# nrf9230_engb_cellcore register map
Vendor: Nordic Semiconductor; Series: nRF92; File version: 1
CPU: CM33 r0p4, little endian, MPU, FPU, 3 interrupt priority bits, 480 interrupts, 8 SAU regions
Registers are 32-bit, read-write, reset 0x0 unless marked. A register's access mark holds for its fields unless they carry their own. Offsets are from the block's base; [hi:lo] are bit positions; lines under a group give offsets from that group; {n}, {i} and the like mark numbered series; 'fields as' and 'values as' point back to an identical list.

## DPPIC0_NS — Distributed programmable peripheral interconnect controller 0
Base 0x44021000
Same registers: DPPIC1_NS 0x44032000, GLOBAL_DPPIC120_NS 0x4F8E1000, GLOBAL_DPPIC130_NS 0x4F922000, GLOBAL_DPPIC131_NS 0x4F981000, GLOBAL_DPPIC132_NS 0x4F991000, GLOBAL_DPPIC133_NS 0x4F9A1000, GLOBAL_DPPIC134_NS 0x4F9B1000, GLOBAL_DPPIC135_NS 0x4F9C1000, GLOBAL_DPPIC136_NS 0x4F9D1000, DPPIC0_S 0x54021000, DPPIC1_S 0x54032000, GLOBAL_DPPIC120_S 0x5F8E1000, GLOBAL_DPPIC130_S 0x5F922000, GLOBAL_DPPIC131_S 0x5F981000, GLOBAL_DPPIC132_S 0x5F991000, GLOBAL_DPPIC133_S 0x5F9A1000, GLOBAL_DPPIC134_S 0x5F9B1000, GLOBAL_DPPIC135_S 0x5F9C1000, GLOBAL_DPPIC136_S 0x5F9D1000
{0x0+8i} TASKS_CHG[{i}] (i=0..3) group — Channel group tasks
  0x00 EN wo — Description cluster: Enable channel group n
    [0] EN — Enable channel group n
      1=Trigger task
  0x04 DIS wo — Description cluster: Disable channel group n
    [0] DIS — Disable channel group n
      1=Trigger task
{0x80+8i} SUBSCRIBE_CHG[{i}] (i=0..3) group — Subscribe configuration for tasks
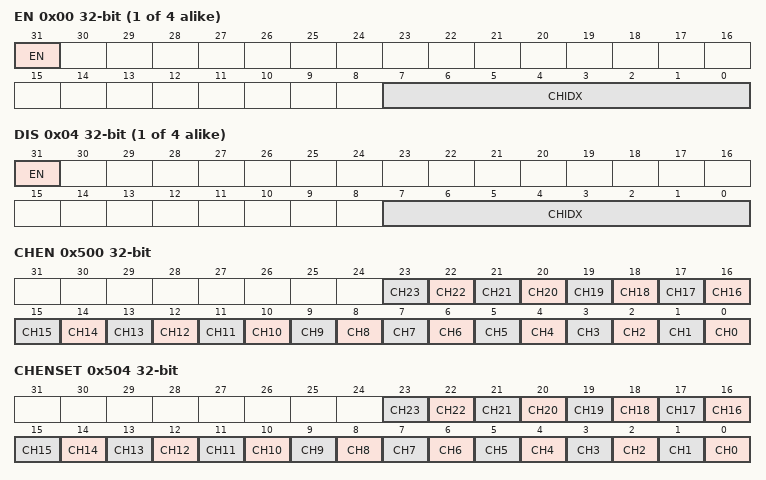
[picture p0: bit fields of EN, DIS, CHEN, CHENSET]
  0x00 EN — Description cluster: Subscribe configuration for task CHG[n].EN
    [31] EN
      0=Disabled (Disable subscription); 1=Enabled (Enable subscription)
    [7:0] CHIDX — DPPI channel that task CHG[n].EN will subscribe to
  0x04 DIS — Description cluster: Subscribe configuration for task CHG[n].DIS
    [31] EN
      values as SUBSCRIBE_CHG[0].EN.EN
    [7:0] CHIDX — DPPI channel that task CHG[n].DIS will subscribe to
0x500 CHEN — Channel enable register
  [all] fields
    0=Disabled (Disable channel); 1=Enabled (Enable channel)
  [n] CH{n} (n=0..23) — Enable or disable channel {n}
0x504 CHENSET write-1-sets — Channel enable set register
  [all] fields
    on read: 0=Disabled (Read: Channel disabled); 1=Enabled (Read: Channel enabled) | on write: 1=Set (Write: Enable channel)
  [n] CH{n} (n=0..23) — Channel {n} enable set register. Writing 0 has no effect.
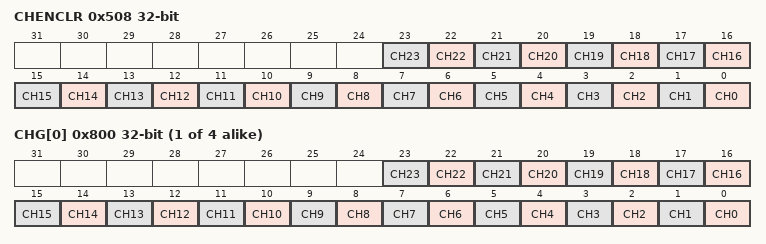
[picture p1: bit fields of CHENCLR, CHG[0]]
0x508 CHENCLR write-1-clears — Channel enable clear register
  [all] fields
    on read: 0=Disabled (Read: Channel disabled); 1=Enabled (Read: Channel enabled) | on write: 1=Clear (Write: Disable channel)
  [n] CH{n} (n=0..23) — Channel {n} enable clear register. Writing 0 has no effect.
{0x800+4i} CHG[{i}] (i=0..3) — Description collection: Channel group n Note: Writes to this register are ignored if either SUBSCRIBE_CHG[n].EN or SUBSCRIBE_CHG[n].DIS is enabled
  [all] fields
    0=Excluded; 1=Included
  [n] CH{n} (n=0..23) — Include or exclude channel {n}

## LFCLKCALIBMEAS_NS — LFCLK calibration measurement 0
Base 0x44023000
Same registers: LFCLKCALIBMEAS_S 0x54023000
0x00 TASKS_START wo — Start Measuring
  [0] TASKS_START
    1=Trigger task
0x04 TASKS_STOP wo — Switch LfClkCalibMeas to STOPPED state. Brings LfClkCalibMeas from SHUTDOWN state to a configurable state before a measurement is launched.
  [0] TASKS_STOP
    1=Trigger task
0x08 TASKS_SHUTDOWN wo — Shut down LfClkCalibMeas
  [0] TASKS_SHUTDOWN
    1=Trigger task
0x100 EVENTS_COMPLETE — Measurement completed
  [0] EVENTS_COMPLETE
    0=NotGenerated (Event not generated); 1=Generated (Event generated)
0x300 INTEN — Enable or disable interrupt
  [0] COMPLETE — Enable or disable interrupt for event COMPLETE
    0=Disabled; 1=Enabled
0x304 INTENSET — Enable interrupt
  [0] COMPLETE — Write '1' to enable interrupt for event COMPLETE
    on read: 0=Disabled (Read: Disabled); 1=Enabled (Read: Enabled) | on write: 1=Set (Enable)
0x308 INTENCLR — Disable interrupt
  [0] COMPLETE — Write '1' to disable interrupt for event COMPLETE
    on read: 0=Disabled (Read: Disabled); 1=Enabled (Read: Enabled) | on write: 1=Clear (Disable)
0x30C INTPEND ro — Pending interrupts
  [0] COMPLETE — Read pending status of interrupt for event COMPLETE
    on read: 0=NotPending (Read: Not pending); 1=Pending (Read: Pending)
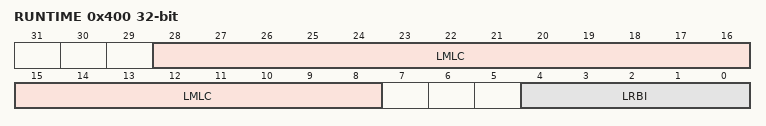
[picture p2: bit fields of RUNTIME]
0x400 RUNTIME ro — Runtime status of the measurement
  [28:8] LMLC — lastMeasuredLfCycle
  [4:0] LRBI — LastRingBufferIndex
{0x404+4i} LCMEAS[{i}] (i=0..19) group — Unspecified
  0x00 LCMEAS ro — Description cluster: LfClk measurement result for the series n
    [31:0] LCMEAS — LfClk measurement result for the series n
0x47C STATE ro — Current running state of the IP
  [1:0] STATE
    0=Shutdown (In SHUTDOWN state); 1=Stopped (In STOPPED state); 2=Running (In RUNNING state); 3=NotApplicable
0x500 MEASLEN — Length of the measurement
  [20:0] MEASLEN

## Notices in the file
Copyright (c) 2010 - 2024, Nordic Semiconductor ASA
All rights reserved.
Redistribution and use in source and binary forms, with or without modification,
are permitted provided that the following conditions are met:
1. Redistributions of source code must retain the above copyright notice, this
list of conditions and the following disclaimer.
2. Redistributions in binary form, except as embedded into a Nordic
Semiconductor ASA integrated circuit in a product or a software update for
such product, must reproduce the above copyright notice, this list of
conditions and the following disclaimer in the documentation and/or other
materials provided with the distribution.
3. Neither the name of Nordic Semiconductor ASA nor the names of its
contributors may be used to endorse or promote products derived from this
software without specific prior written permission.
4. This software, with or without modification, must only be used with a
Nordic Semiconductor ASA integrated circuit.
5. Any software provided in binary form under this license must not be reverse
engineered, decompiled, modified and/or disassembled.
THIS SOFTWARE IS PROVIDED BY NORDIC SEMICONDUCTOR ASA "AS IS" AND ANY EXPRESS
OR IMPLIED WARRANTIES, INCLUDING, BUT NOT LIMITED TO, THE IMPLIED WARRANTIES
OF MERCHANTABILITY, NONINFRINGEMENT, AND FITNESS FOR A PARTICULAR PURPOSE ARE
DISCLAIMED. IN NO EVENT SHALL NORDIC SEMICONDUCTOR ASA OR CONTRIBUTORS BE
LIABLE FOR ANY DIRECT, INDIRECT, INCIDENTAL, SPECIAL, EXEMPLARY, OR
CONSEQUENTIAL DAMAGES (INCLUDING, BUT NOT LIMITED TO, PROCUREMENT OF SUBSTITUTE
GOODS OR SERVICES; LOSS OF USE, DATA, OR PROFITS; OR BUSINESS INTERRUPTION)
HOWEVER CAUSED AND ON ANY THEORY OF LIABILITY, WHETHER IN CONTRACT, STRICT
LIABILITY, OR TORT (INCLUDING NEGLIGENCE OR OTHERWISE) ARISING IN ANY WAY OUT
OF THE USE OF THIS SOFTWARE, EVEN IF ADVISED OF THE POSSIBILITY OF SUCH DAMAGE.
